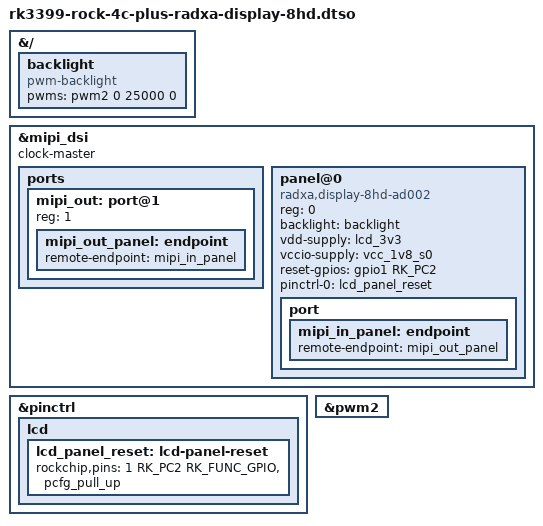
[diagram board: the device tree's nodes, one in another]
// SPDX-License-Identifier: (GPL-2.0+ OR MIT)
/*
 * Copyright (c) 2019 Radxa Limited
 * Copyright (c) 2022 Edgeble AI Technologies Pvt. Ltd.
 *
 * DT-overlay for the Radxa Display 8HD connected to Radxa 4C+
 */

/dts-v1/;
/plugin/;

#include <dt-bindings/gpio/gpio.h>
#include <dt-bindings/pinctrl/rockchip.h>

&{/} {
	backlight: backlight {
		compatible = "pwm-backlight";
		pwms = <&pwm2 0 25000 0>;
	};
};

&mipi_dsi {
	clock-master;
	#address-cells = <1>;
	#size-cells = <0>;
	status = "okay";

	ports {
		#address-cells = <1>;
		#size-cells = <0>;

		mipi_out: port@1 {
			reg = <1>;

			mipi_out_panel: endpoint {
				remote-endpoint = <&mipi_in_panel>;
			};
		};
	};

	panel@0 {
		compatible = "radxa,display-8hd-ad002", "jadard,jd9365da-h3";
		reg = <0>;
		backlight = <&backlight>;
		vdd-supply = <&lcd_3v3>;
		vccio-supply = <&vcc_1v8_s0>;
		reset-gpios = <&gpio1 RK_PC2 GPIO_ACTIVE_HIGH>;
		pinctrl-names = "default";
		pinctrl-0 = <&lcd_panel_reset>;

		port {
			mipi_in_panel: endpoint {
				remote-endpoint = <&mipi_out_panel>;
			};
		};
	};
};

&pinctrl {
	lcd {
		lcd_panel_reset: lcd-panel-reset {
			rockchip,pins = <1 RK_PC2 RK_FUNC_GPIO &pcfg_pull_up>;
		};
	};
};

&pwm2 {
	status = "okay";
};
